# ADC10_1 register map
Vendor: Texas Instruments
Peripheral module from a debugger description file (folder msp430).
Registers are 16-bit, read-write, reset 0x0 unless marked. A register's access mark holds for its fields unless they carry their own. Offsets are as the file gives them; lines under a group give offsets from that group; [hi:lo] are bit positions; {n}, {i} and the like mark numbered series; 'fields as' and 'values as' point back to an identical list; <NAME> marks a mode.

## ADC10
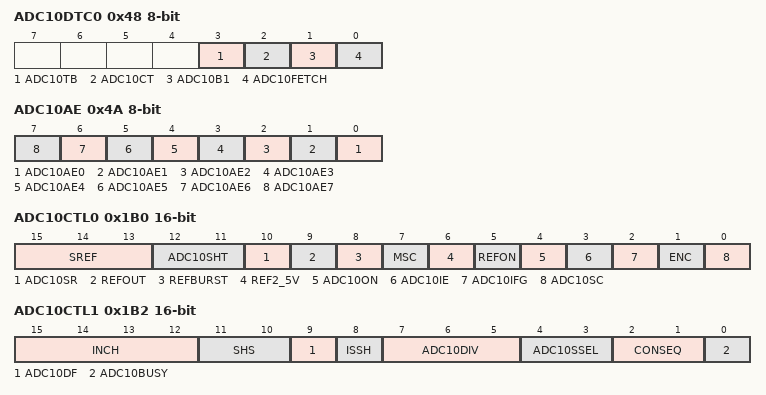
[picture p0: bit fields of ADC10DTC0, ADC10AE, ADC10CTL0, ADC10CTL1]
0x48 ADC10DTC0 8-bit — ADC10 Data Transfer Control 0
  [3] ADC10TB — ADC10 two-block mode
  [2] ADC10CT — ADC10 continuous transfer
  [1] ADC10B1 — ADC10 block one
  [0] ADC10FETCH — This bit should normally be reset
0x49 ADC10DTC1 8-bit access not given reset not defined — ADC10 Data Transfer Control 1
0x4A ADC10AE 8-bit — ADC10 Analog Enable
  [n] ADC10AE{n} (n=0..7) — ADC10 External Input Enable {n}
0x1B0 ADC10CTL0 — ADC10 Control 0
  [15:13] SREF — ADC10 Reference Select Bit: 0
    0=VR+ = AVCC and VR- = AVSS; 1=VR+ = VREF+ and VR- = AVSS; 2=VR+ = VEREF+ and VR- = AVSS; 3=VR+ = VEREF+ and VR- = AVSS; 4=VR+ = AVCC and VR- = VREF-/VEREF-; 5=VR+ = VREF+ and VR- = VREF-/VEREF-; 6=VR+ = VEREF+ and VR- = VREF-/VEREF-; 7=VR+ = VEREF+ and VR- = VREF-/VEREF-
  [12:11] ADC10SHT — ADC10 Sample Hold Select Bit: 0
    0=4 x ADC10CLKs; 1=8 x ADC10CLKs; 2=16 x ADC10CLKs; 3=64 x ADC10CLKs
  [10] ADC10SR — ADC10 Sampling Rate 0:200ksps / 1:50ksps
  [9] REFOUT — ADC10 Enalbe output of Ref.
  [8] REFBURST — ADC10 Reference Burst Mode
  [7] MSC — ADC10 Multiple SampleConversion
  [6] REF2_5V — ADC10 Ref 0:1.5V / 1:2.5V
  [5] REFON — ADC10 Reference on
  [4] ADC10ON — ADC10 On/Enable
  [3] ADC10IE — ADC10 Interrupt Enalbe
  [2] ADC10IFG — ADC10 Interrupt Flag
  [1] ENC — ADC10 Enable Conversion
  [0] ADC10SC — ADC10 Start Conversion
0x1B2 ADC10CTL1 — ADC10 Control 1
  [15:12] INCH — ADC10 Input Channel Select Bit: 0
    {v}=Selects Channel {v} (v=0..15)
  [11:10] SHS — ADC10 Sample/Hold Source Bit: 0
    0=ADC10SC; 1=TA3 OUT1; 2=TA3 OUT0; 3=TA3 OUT2
  [9] ADC10DF — ADC10 Data Format 0:binary 1:2's complement
  [8] ISSH — ADC10 Invert Sample Hold Signal
  [7:5] ADC10DIV — ADC10 Clock Divider Select Bit: 0
    {v}=ADC10 Clock Divider Select {v} (v=0..7)
  [4:3] ADC10SSEL — ADC10 Clock Source Select Bit: 0
    0=ADC10OSC; 1=ACLK; 2=MCLK; 3=SMCLK
  [2:1] CONSEQ — ADC10 Conversion Sequence Select 0
    0=Single channel single conversion; 1=Sequence of channels; 2=Repeat single channel; 3=Repeat sequence of channels
  [0] ADC10BUSY
0x1B4 ADC10MEM access not given reset not defined — ADC10 Memory
0x1BC ADC10SA access not given reset not defined — ADC10 Data Transfer Start Address
